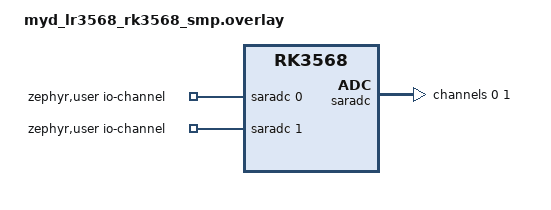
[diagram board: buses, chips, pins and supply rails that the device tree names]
/*
 * SPDX-FileCopyrightText: Copyright The Zephyr Project Contributors
 * SPDX-License-Identifier: Apache-2.0
 */

#include <zephyr/dt-bindings/adc/adc.h>

/* Channel 0: S2 & S5 key ladder; channels 1 & 2: J14 pins 35 & 36 */

/ {
	zephyr,user {
		io-channels = <&saradc 0>, <&saradc 1>;
	};
};

&saradc {
	channel@0 {
		reg = <0>;
		zephyr,gain = "ADC_GAIN_1";
		zephyr,reference = "ADC_REF_INTERNAL";
		zephyr,acquisition-time = <ADC_ACQ_TIME_DEFAULT>;
		zephyr,resolution = <10>;
	};

	channel@1 {
		reg = <1>;
		zephyr,gain = "ADC_GAIN_1";
		zephyr,reference = "ADC_REF_INTERNAL";
		zephyr,acquisition-time = <ADC_ACQ_TIME_DEFAULT>;
		zephyr,resolution = <10>;
	};
};
